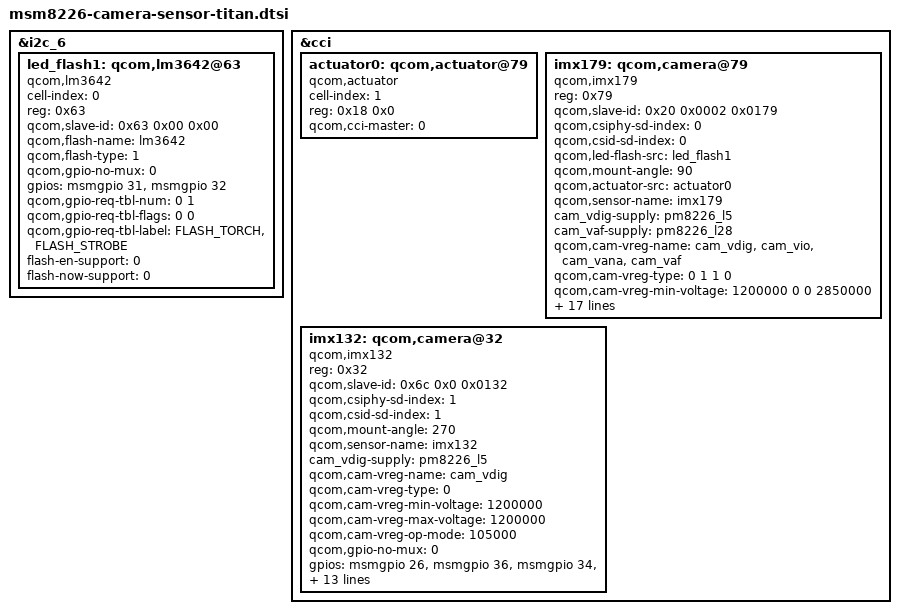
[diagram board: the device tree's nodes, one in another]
/*
 * Copyright (c) 2014, The Linux Foundation. All rights reserved.
 *
 * This program is free software; you can redistribute it and/or modify
 * it under the terms of the GNU General Public License version 2 and
 * only version 2 as published by the Free Software Foundation.
 *
 * This program is distributed in the hope that it will be useful,
 * but WITHOUT ANY WARRANTY; without even the implied warranty of
 * MERCHANTABILITY or FITNESS FOR A PARTICULAR PURPOSE.  See the
 * GNU General Public License for more details.
 */

&i2c_6 {
	status = "ok";

	led_flash1: qcom,lm3642@63{
		cell-index = <0>;
		reg = <0x63>;
		qcom,slave-id = <0x63 0x00 0x00>;
		compatible = "qcom,lm3642";
		qcom,flash-name = "lm3642";
		qcom,flash-type = <1>;
		qcom,gpio-no-mux = <0>;
		gpios = <&msmgpio 31 0>,
			<&msmgpio 32 0>;
		qcom,gpio-req-tbl-num = <0 1>;
		qcom,gpio-req-tbl-flags = <0 0>;
		qcom,gpio-req-tbl-label = "FLASH_TORCH",
					"FLASH_STROBE";
		flash-en-support = <0>;
		flash-now-support = <0>;
	};
};

&cci {
	actuator0: qcom,actuator@79 {
		cell-index = <1>;
		reg = <0x18 0x0>;
		compatible = "qcom,actuator";
		qcom,cci-master = <0>;
	};

	imx179: qcom,camera@79 {
		compatible = "qcom,imx179";
		reg = <0x79>;
		qcom,slave-id = <0x20 0x0002 0x0179>;
		qcom,csiphy-sd-index = <0>;
		qcom,csid-sd-index = <0>;
		qcom,led-flash-src = <&led_flash1>;
		qcom,mount-angle = <90>;
		qcom,actuator-src = <&actuator0>;
		qcom,sensor-name = "imx179";
		cam_vdig-supply = <&pm8226_l5>;
		cam_vaf-supply = <&pm8226_l28>;
		qcom,cam-vreg-name = "cam_vdig", "cam_vio", "cam_vana", "cam_vaf";
		qcom,cam-vreg-type = <0 1 1 0>;
		qcom,cam-vreg-min-voltage = <1200000 0 0 2850000>;
		qcom,cam-vreg-max-voltage = <1200000 0 0 2850000>;
		qcom,cam-vreg-op-mode = <105000 0 0 100000>;
		qcom,gpio-no-mux = <0>;
		gpios = <&msmgpio 26 0>,
			<&msmgpio 27 0>,
			<&msmgpio 33 0>,
			<&msmgpio 37 0>;
		qcom,gpio-vana = <1>;
		qcom,gpio-vio = <2>;
		qcom,gpio-reset = <3>;
		qcom,gpio-req-tbl-num = <0 1 2 3>;
		qcom,gpio-req-tbl-flags = <0 0 0 0>;
		qcom,gpio-req-tbl-label = "CAMIF_MCLK",
					"CAM_VANA",
					"CAM_VIO",
					"CAM_RESET";
		qcom,csi-lane-assign = <0x4320>;
		qcom,csi-lane-mask = <0x1F>;
		qcom,sensor-position = <0>;
		qcom,sensor-mode = <0>;
		qcom,cci-master = <0>;
		status = "ok";
		};

	imx132: qcom,camera@32 {
		compatible = "qcom,imx132";
		reg = <0x32>;
		qcom,slave-id = <0x6c 0x0 0x0132>;
		qcom,csiphy-sd-index = <1>;
		qcom,csid-sd-index = <1>;
		qcom,mount-angle = <270>;
		qcom,sensor-name = "imx132";
//		qcom,eeprom-src = <&eeprom0>;/*TBD*/
		cam_vdig-supply = <&pm8226_l5>;
		qcom,cam-vreg-name = "cam_vdig";
		qcom,cam-vreg-type = <0>;
		qcom,cam-vreg-min-voltage = <1200000>;
		qcom,cam-vreg-max-voltage = <1200000>;
		qcom,cam-vreg-op-mode = <105000>;
		qcom,gpio-no-mux = <0>;
		gpios = <&msmgpio 26 0>,
			<&msmgpio 36 0>,
			<&msmgpio 34 0>,
			<&msmgpio 35 0>;
		qcom,gpio-vio = <1>;
		qcom,gpio-vana = <2>;
		qcom,gpio-standby = <3>;
		qcom,gpio-req-tbl-num = <0 1 2 3>;
		qcom,gpio-req-tbl-flags = <0 0 0 0>;
		qcom,gpio-req-tbl-label = "CAMIF_MCLK",
					"CAM_VIO",
					"CAM_VANA",
					"CAM_STANDBY";
		qcom,csi-lane-assign = <0x4320>;
		qcom,csi-lane-mask = <0x3>;
		qcom,sensor-position = <1>;
		qcom,sensor-mode = <1>;
		qcom,cci-master = <0>;
		status = "ok";
		};

	};
